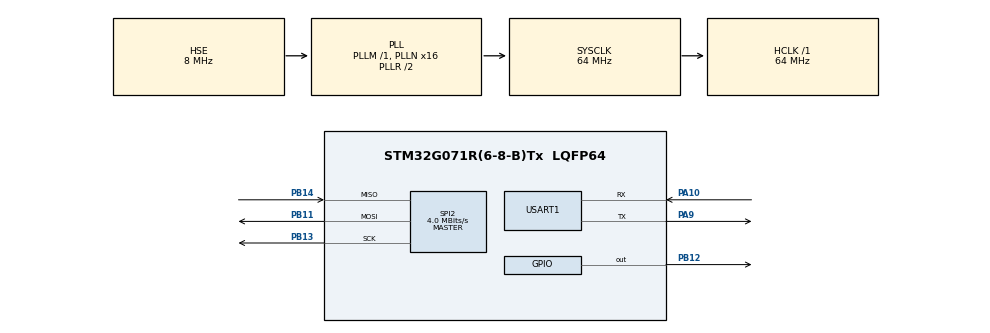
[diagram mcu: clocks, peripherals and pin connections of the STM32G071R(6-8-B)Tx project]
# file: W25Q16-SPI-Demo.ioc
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Mcu.Family=STM32G0
Mcu.Name=STM32G071R(6-8-B)Tx
Mcu.Package=LQFP64
PA10.Mode=Asynchronous
PA10.Signal=USART1_RX
PA13.Mode=Serial_Wire
PA13.Signal=SYS_SWDIO
PA14-BOOT0.Mode=Serial_Wire
PA14-BOOT0.Signal=SYS_SWCLK
PA9.Mode=Asynchronous
PA9.Signal=USART1_TX
PB11.Mode=Full_Duplex_Master
PB11.Signal=SPI2_MOSI
PB12.GPIO_PuPd=GPIO_PULLUP
PB12.Signal=GPIO_Output
PB13.Mode=Full_Duplex_Master
PB13.Signal=SPI2_SCK
PB14.Mode=Full_Duplex_Master
PB14.Signal=SPI2_MISO
PF0-OSC_IN\ (PF0).Mode=HSE-External-Oscillator
PF0-OSC_IN\ (PF0).Signal=RCC_OSC_IN
PF1-OSC_OUT\ (PF1).Mode=HSE-External-Oscillator
PF1-OSC_OUT\ (PF1).Signal=RCC_OSC_OUT
ProjectManager.HeapSize=0x200
ProjectManager.StackSize=0x400
ProjectManager.TargetToolchain=MDK-ARM V5
RCC.ADCFreq_Value=64000000
RCC.AHBFreq_Value=64000000
RCC.CortexFreq_Value=64000000
RCC.EXTERNAL_CLOCK_VALUE=48000
RCC.HCLKFreq_Value=64000000
RCC.HSE_VALUE=8000000
RCC.HSI_VALUE=16000000
RCC.LSE_VALUE=32768
RCC.PLLN=16
RCC.PLLSourceVirtual=RCC_PLLSOURCE_HSE
RCC.SYSCLKFreq_VALUE=64000000
RCC.SYSCLKSource=RCC_SYSCLKSOURCE_PLLCLK
RCC.VCOOutputFreq_Value=128000000
SPI2.BaudRatePrescaler=SPI_BAUDRATEPRESCALER_16
SPI2.CalculateBaudRate=4.0 MBits/s
SPI2.DataSize=SPI_DATASIZE_8BIT
SPI2.Direction=SPI_DIRECTION_2LINES
SPI2.Mode=SPI_MODE_MASTER
SPI2.VirtualType=VM_MASTER
USART1.VirtualMode-Asynchronous=VM_ASYNC
VP_SYS_VS_DBSignals.Mode=DisableDeadBatterySignals
board=custom

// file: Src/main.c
/* USER CODE BEGIN Header */
/**
  ******************************************************************************
  * @file           : main.c
  * @brief          : Main program body
  ******************************************************************************
  * @attention
  *
  * <h2><center>&copy; Copyright (c) 2020 STMicroelectronics.
  * All rights reserved.</center></h2>
  *
  * This software component is licensed by ST under BSD 3-Clause license,
  * the "License"; You may not use this file except in compliance with the
  * License. You may obtain a copy of the License at:
  *                        opensource.org/licenses/BSD-3-Clause
  *
  ******************************************************************************
  */
/* USER CODE END Header */

#include "main.h"
#include "spi.h"
#include "usart.h"
#include "gpio.h"

/* USER CODE BEGIN Includes */
#include "w25q16.h"
#include <stdio.h>
/* USER CODE END Includes */

void SystemClock_Config(void);

/* USER CODE BEGIN 0 */
uint8_t writebuff[10]={2,3,4,5,6,10,77,99,10,29};
uint32_t address=0x000000;
uint8_t receive_data[10];
/* USER CODE END 0 */

int main(void)
{

  /* MCU Configuration--------------------------------------------------------*/

  /* Reset of all peripherals, Initializes the Flash interface and the Systick. */
  HAL_Init();

  /* Configure the system clock */
  SystemClock_Config();

  /* Initialize all configured peripherals */
  MX_GPIO_Init();
  MX_SPI2_Init();
  MX_USART1_UART_Init();
  /* USER CODE BEGIN 2 */

/*Read JEDEC ID*/
  printf("\r\n%X",READ_JEDECID(&hspi2));
/*END Read JEDEC ID*/

  /* USER CODE END 2 */

  /* Infinite loop */
  while (1)
  {

  }
}

void SystemClock_Config(void)
{
  RCC_OscInitTypeDef RCC_OscInitStruct = {0};
  RCC_ClkInitTypeDef RCC_ClkInitStruct = {0};
  RCC_PeriphCLKInitTypeDef PeriphClkInit = {0};

  /** Configure the main internal regulator output voltage
  */
  HAL_PWREx_ControlVoltageScaling(PWR_REGULATOR_VOLTAGE_SCALE1);
  /** Initializes the CPU, AHB and APB busses clocks
  */
  RCC_OscInitStruct.OscillatorType = RCC_OSCILLATORTYPE_HSE;
  RCC_OscInitStruct.HSEState = RCC_HSE_ON;
  RCC_OscInitStruct.PLL.PLLState = RCC_PLL_ON;
  RCC_OscInitStruct.PLL.PLLSource = RCC_PLLSOURCE_HSE;
  RCC_OscInitStruct.PLL.PLLM = RCC_PLLM_DIV1;
  RCC_OscInitStruct.PLL.PLLN = 16;
  RCC_OscInitStruct.PLL.PLLP = RCC_PLLP_DIV2;
  RCC_OscInitStruct.PLL.PLLQ = RCC_PLLQ_DIV2;
  RCC_OscInitStruct.PLL.PLLR = RCC_PLLR_DIV2;
  if (HAL_RCC_OscConfig(&RCC_OscInitStruct) != HAL_OK)
  {
    Error_Handler();
  }
  /** Initializes the CPU, AHB and APB busses clocks
  */
  RCC_ClkInitStruct.ClockType = RCC_CLOCKTYPE_HCLK|RCC_CLOCKTYPE_SYSCLK
                              |RCC_CLOCKTYPE_PCLK1;
  RCC_ClkInitStruct.SYSCLKSource = RCC_SYSCLKSOURCE_PLLCLK;
  RCC_ClkInitStruct.AHBCLKDivider = RCC_SYSCLK_DIV1;
  RCC_ClkInitStruct.APB1CLKDivider = RCC_HCLK_DIV1;

  if (HAL_RCC_ClockConfig(&RCC_ClkInitStruct, FLASH_LATENCY_2) != HAL_OK)
  {
    Error_Handler();
  }
  /** Initializes the peripherals clocks
  */
  PeriphClkInit.PeriphClockSelection = RCC_PERIPHCLK_USART1;
  PeriphClkInit.Usart1ClockSelection = RCC_USART1CLKSOURCE_PCLK1;
  if (HAL_RCCEx_PeriphCLKConfig(&PeriphClkInit) != HAL_OK)
  {
    Error_Handler();
  }
}

void Error_Handler(void)
{
}

/************************ (C) COPYRIGHT STMicroelectronics *****END OF FILE****/
